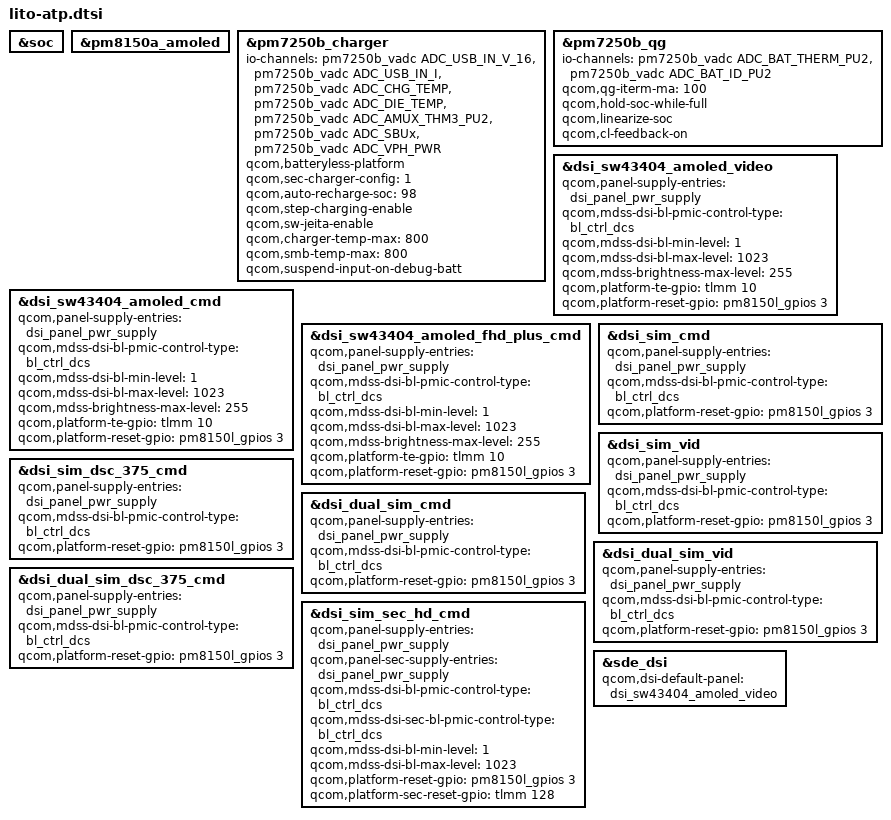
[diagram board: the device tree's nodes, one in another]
#include "lito-audio-overlay.dtsi"
#include "lito-pmic-overlay.dtsi"
#include "lito-sde-display.dtsi"

&soc {

};

&pm8150a_amoled {
	status = "ok";
};

&pm7250b_charger {
	status = "ok";
	io-channels = <&pm7250b_vadc ADC_USB_IN_V_16>,
		      <&pm7250b_vadc ADC_USB_IN_I>,
		      <&pm7250b_vadc ADC_CHG_TEMP>,
		      <&pm7250b_vadc ADC_DIE_TEMP>,
		      <&pm7250b_vadc ADC_AMUX_THM3_PU2>,
		      <&pm7250b_vadc ADC_SBUx>,
		      <&pm7250b_vadc ADC_VPH_PWR>;
	io-channel-names = "usb_in_voltage",
			   "usb_in_current",
			   "chg_temp",
			   "die_temp",
			   "conn_temp",
			   "sbux_res",
			   "vph_voltage";
	qcom,batteryless-platform;
	qcom,sec-charger-config = <1>;
	qcom,auto-recharge-soc = <98>;
	qcom,step-charging-enable;
	qcom,sw-jeita-enable;
	qcom,charger-temp-max = <800>;
	qcom,smb-temp-max = <800>;
	qcom,suspend-input-on-debug-batt;
};

&pm7250b_qg {
	status = "ok";
	io-channels = <&pm7250b_vadc ADC_BAT_THERM_PU2>,
		      <&pm7250b_vadc ADC_BAT_ID_PU2>;
	io-channel-names = "batt-therm",
			   "batt-id";
	qcom,qg-iterm-ma = <100>;
	qcom,hold-soc-while-full;
	qcom,linearize-soc;
	qcom,cl-feedback-on;
};

&dsi_sw43404_amoled_video {
	qcom,panel-supply-entries = <&dsi_panel_pwr_supply>;
	qcom,mdss-dsi-bl-pmic-control-type = "bl_ctrl_dcs";
	qcom,mdss-dsi-bl-min-level = <1>;
	qcom,mdss-dsi-bl-max-level = <1023>;
	qcom,mdss-brightness-max-level = <255>;
	qcom,platform-te-gpio = <&tlmm 10 0>;
	qcom,platform-reset-gpio = <&pm8150l_gpios 3 0>;
};

&dsi_sw43404_amoled_cmd {
	qcom,panel-supply-entries = <&dsi_panel_pwr_supply>;
	qcom,mdss-dsi-bl-pmic-control-type = "bl_ctrl_dcs";
	qcom,mdss-dsi-bl-min-level = <1>;
	qcom,mdss-dsi-bl-max-level = <1023>;
	qcom,mdss-brightness-max-level = <255>;
	qcom,platform-te-gpio = <&tlmm 10 0>;
	qcom,platform-reset-gpio = <&pm8150l_gpios 3 0>;
};

&dsi_sw43404_amoled_fhd_plus_cmd {
	qcom,panel-supply-entries = <&dsi_panel_pwr_supply>;
	qcom,mdss-dsi-bl-pmic-control-type = "bl_ctrl_dcs";
	qcom,mdss-dsi-bl-min-level = <1>;
	qcom,mdss-dsi-bl-max-level = <1023>;
	qcom,mdss-brightness-max-level = <255>;
	qcom,platform-te-gpio = <&tlmm 10 0>;
	qcom,platform-reset-gpio = <&pm8150l_gpios 3 0>;
};

&dsi_sim_cmd {
	qcom,panel-supply-entries = <&dsi_panel_pwr_supply>;
	qcom,mdss-dsi-bl-pmic-control-type = "bl_ctrl_dcs";
	qcom,platform-reset-gpio = <&pm8150l_gpios 3 0>;
};

&dsi_sim_vid {
	qcom,panel-supply-entries = <&dsi_panel_pwr_supply>;
	qcom,mdss-dsi-bl-pmic-control-type = "bl_ctrl_dcs";
	qcom,platform-reset-gpio = <&pm8150l_gpios 3 0>;
};

&dsi_sim_dsc_375_cmd {
	qcom,panel-supply-entries = <&dsi_panel_pwr_supply>;
	qcom,mdss-dsi-bl-pmic-control-type = "bl_ctrl_dcs";
	qcom,platform-reset-gpio = <&pm8150l_gpios 3 0>;
};

&dsi_dual_sim_cmd {
	qcom,panel-supply-entries = <&dsi_panel_pwr_supply>;
	qcom,mdss-dsi-bl-pmic-control-type = "bl_ctrl_dcs";
	qcom,platform-reset-gpio = <&pm8150l_gpios 3 0>;
};

&dsi_dual_sim_vid {
	qcom,panel-supply-entries = <&dsi_panel_pwr_supply>;
	qcom,mdss-dsi-bl-pmic-control-type = "bl_ctrl_dcs";
	qcom,platform-reset-gpio = <&pm8150l_gpios 3 0>;
};

&dsi_dual_sim_dsc_375_cmd {
	qcom,panel-supply-entries = <&dsi_panel_pwr_supply>;
	qcom,mdss-dsi-bl-pmic-control-type = "bl_ctrl_dcs";
	qcom,platform-reset-gpio = <&pm8150l_gpios 3 0>;
};

&dsi_sim_sec_hd_cmd {
	qcom,panel-supply-entries = <&dsi_panel_pwr_supply>;
	qcom,panel-sec-supply-entries = <&dsi_panel_pwr_supply>;
	qcom,mdss-dsi-bl-pmic-control-type = "bl_ctrl_dcs";
	qcom,mdss-dsi-sec-bl-pmic-control-type = "bl_ctrl_dcs";
	qcom,mdss-dsi-bl-min-level = <1>;
	qcom,mdss-dsi-bl-max-level = <1023>;
	qcom,platform-reset-gpio = <&pm8150l_gpios 3 0>;
	qcom,platform-sec-reset-gpio = <&tlmm 128 0>;
};

&sde_dsi {
	qcom,dsi-default-panel = <&dsi_sw43404_amoled_video>;
};
